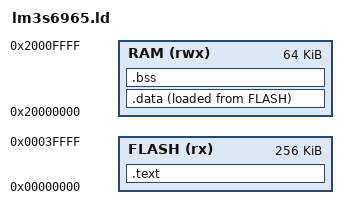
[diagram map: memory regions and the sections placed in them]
MEMORY
{
    FLASH (rx)  : ORIGIN = 0x00000000, LENGTH = 256K
    RAM   (rwx) : ORIGIN = 0x20000000, LENGTH = 64K
}

SECTIONS
{
    .text :
    {
        KEEP(*(.vector_table))
        *(.text*)
        *(.rodata*)
    } > FLASH

    .data :
    {
        *(.data*)
    } > RAM AT > FLASH

    .bss :
    {
        *(.bss*)
        *(COMMON)
    } > RAM
}
